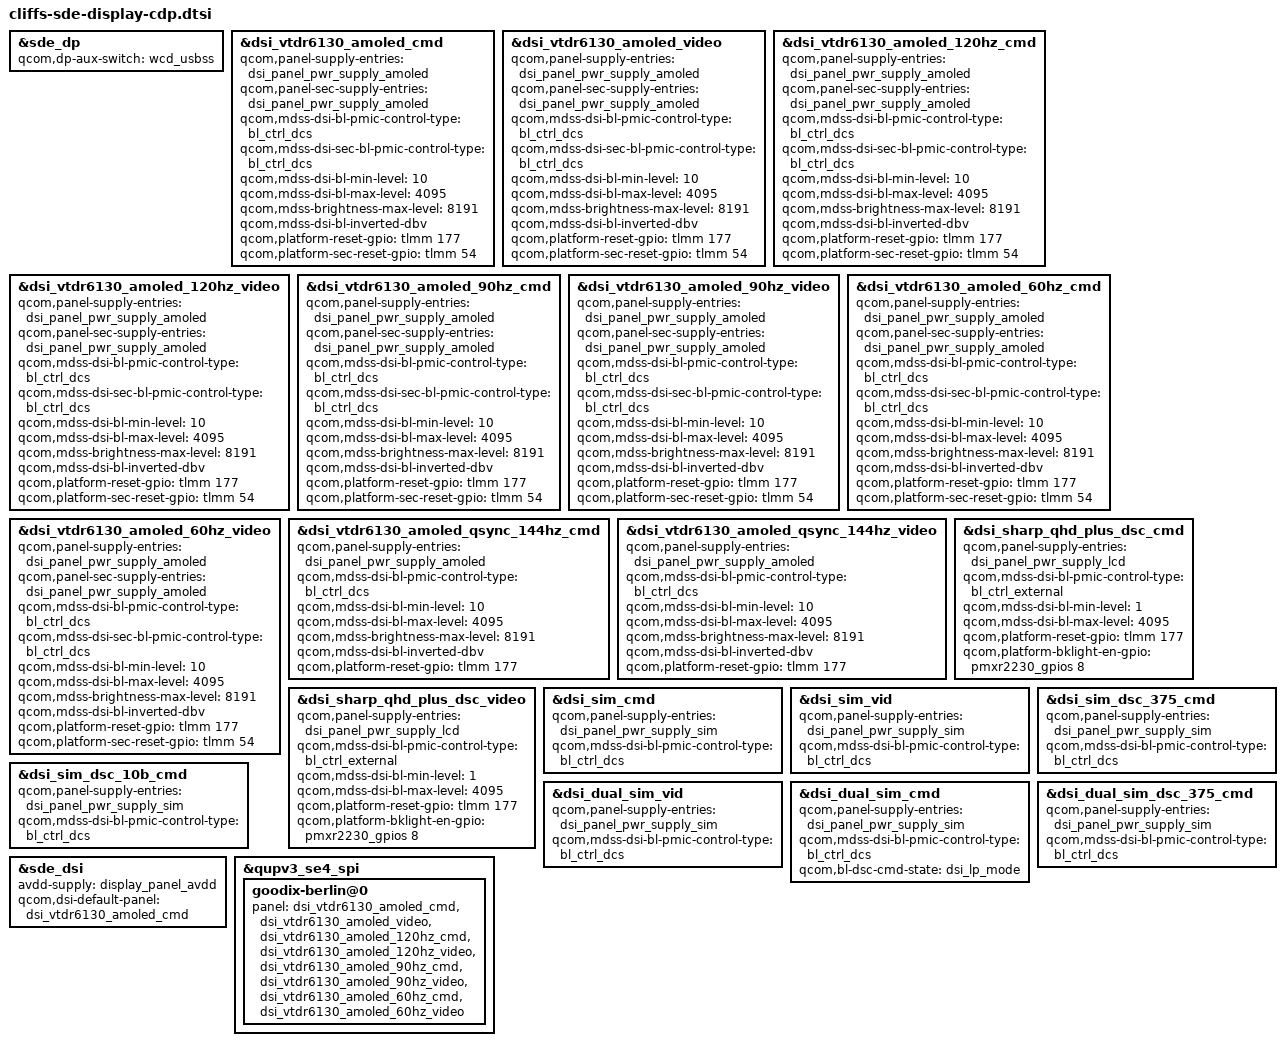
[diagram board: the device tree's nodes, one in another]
#include "cliffs-sde-display.dtsi"

&sde_dp {
	qcom,dp-aux-switch = <&wcd_usbss>;
};

&dsi_vtdr6130_amoled_cmd {
	qcom,panel-supply-entries = <&dsi_panel_pwr_supply_amoled>;
	qcom,panel-sec-supply-entries = <&dsi_panel_pwr_supply_amoled>;
	qcom,mdss-dsi-bl-pmic-control-type = "bl_ctrl_dcs";
	qcom,mdss-dsi-sec-bl-pmic-control-type = "bl_ctrl_dcs";
	qcom,mdss-dsi-bl-min-level = <10>;
	qcom,mdss-dsi-bl-max-level = <4095>;
	qcom,mdss-brightness-max-level = <8191>;
	qcom,mdss-dsi-bl-inverted-dbv;
	qcom,platform-reset-gpio = <&tlmm 177 0>;
	qcom,platform-sec-reset-gpio = <&tlmm 54 0>;
};

&dsi_vtdr6130_amoled_video {
	qcom,panel-supply-entries = <&dsi_panel_pwr_supply_amoled>;
	qcom,panel-sec-supply-entries = <&dsi_panel_pwr_supply_amoled>;
	qcom,mdss-dsi-bl-pmic-control-type = "bl_ctrl_dcs";
	qcom,mdss-dsi-sec-bl-pmic-control-type = "bl_ctrl_dcs";
	qcom,mdss-dsi-bl-min-level = <10>;
	qcom,mdss-dsi-bl-max-level = <4095>;
	qcom,mdss-brightness-max-level = <8191>;
	qcom,mdss-dsi-bl-inverted-dbv;
	qcom,platform-reset-gpio = <&tlmm 177 0>;
	qcom,platform-sec-reset-gpio = <&tlmm 54 0>;
};

&dsi_vtdr6130_amoled_120hz_cmd {
	qcom,panel-supply-entries = <&dsi_panel_pwr_supply_amoled>;
	qcom,panel-sec-supply-entries = <&dsi_panel_pwr_supply_amoled>;
	qcom,mdss-dsi-bl-pmic-control-type = "bl_ctrl_dcs";
	qcom,mdss-dsi-sec-bl-pmic-control-type = "bl_ctrl_dcs";
	qcom,mdss-dsi-bl-min-level = <10>;
	qcom,mdss-dsi-bl-max-level = <4095>;
	qcom,mdss-brightness-max-level = <8191>;
	qcom,mdss-dsi-bl-inverted-dbv;
	qcom,platform-reset-gpio = <&tlmm 177 0>;
	qcom,platform-sec-reset-gpio = <&tlmm 54 0>;
};

&dsi_vtdr6130_amoled_120hz_video {
	qcom,panel-supply-entries = <&dsi_panel_pwr_supply_amoled>;
	qcom,panel-sec-supply-entries = <&dsi_panel_pwr_supply_amoled>;
	qcom,mdss-dsi-bl-pmic-control-type = "bl_ctrl_dcs";
	qcom,mdss-dsi-sec-bl-pmic-control-type = "bl_ctrl_dcs";
	qcom,mdss-dsi-bl-min-level = <10>;
	qcom,mdss-dsi-bl-max-level = <4095>;
	qcom,mdss-brightness-max-level = <8191>;
	qcom,mdss-dsi-bl-inverted-dbv;
	qcom,platform-reset-gpio = <&tlmm 177 0>;
	qcom,platform-sec-reset-gpio = <&tlmm 54 0>;
};

&dsi_vtdr6130_amoled_90hz_cmd {
	qcom,panel-supply-entries = <&dsi_panel_pwr_supply_amoled>;
	qcom,panel-sec-supply-entries = <&dsi_panel_pwr_supply_amoled>;
	qcom,mdss-dsi-bl-pmic-control-type = "bl_ctrl_dcs";
	qcom,mdss-dsi-sec-bl-pmic-control-type = "bl_ctrl_dcs";
	qcom,mdss-dsi-bl-min-level = <10>;
	qcom,mdss-dsi-bl-max-level = <4095>;
	qcom,mdss-brightness-max-level = <8191>;
	qcom,mdss-dsi-bl-inverted-dbv;
	qcom,platform-reset-gpio = <&tlmm 177 0>;
	qcom,platform-sec-reset-gpio = <&tlmm 54 0>;
};

&dsi_vtdr6130_amoled_90hz_video {
	qcom,panel-supply-entries = <&dsi_panel_pwr_supply_amoled>;
	qcom,panel-sec-supply-entries = <&dsi_panel_pwr_supply_amoled>;
	qcom,mdss-dsi-bl-pmic-control-type = "bl_ctrl_dcs";
	qcom,mdss-dsi-sec-bl-pmic-control-type = "bl_ctrl_dcs";
	qcom,mdss-dsi-bl-min-level = <10>;
	qcom,mdss-dsi-bl-max-level = <4095>;
	qcom,mdss-brightness-max-level = <8191>;
	qcom,mdss-dsi-bl-inverted-dbv;
	qcom,platform-reset-gpio = <&tlmm 177 0>;
	qcom,platform-sec-reset-gpio = <&tlmm 54 0>;
};

&dsi_vtdr6130_amoled_60hz_cmd {
	qcom,panel-supply-entries = <&dsi_panel_pwr_supply_amoled>;
	qcom,panel-sec-supply-entries = <&dsi_panel_pwr_supply_amoled>;
	qcom,mdss-dsi-bl-pmic-control-type = "bl_ctrl_dcs";
	qcom,mdss-dsi-sec-bl-pmic-control-type = "bl_ctrl_dcs";
	qcom,mdss-dsi-bl-min-level = <10>;
	qcom,mdss-dsi-bl-max-level = <4095>;
	qcom,mdss-brightness-max-level = <8191>;
	qcom,mdss-dsi-bl-inverted-dbv;
	qcom,platform-reset-gpio = <&tlmm 177 0>;
	qcom,platform-sec-reset-gpio = <&tlmm 54 0>;
};

&dsi_vtdr6130_amoled_60hz_video {
	qcom,panel-supply-entries = <&dsi_panel_pwr_supply_amoled>;
	qcom,panel-sec-supply-entries = <&dsi_panel_pwr_supply_amoled>;
	qcom,mdss-dsi-bl-pmic-control-type = "bl_ctrl_dcs";
	qcom,mdss-dsi-sec-bl-pmic-control-type = "bl_ctrl_dcs";
	qcom,mdss-dsi-bl-min-level = <10>;
	qcom,mdss-dsi-bl-max-level = <4095>;
	qcom,mdss-brightness-max-level = <8191>;
	qcom,mdss-dsi-bl-inverted-dbv;
	qcom,platform-reset-gpio = <&tlmm 177 0>;
	qcom,platform-sec-reset-gpio = <&tlmm 54 0>;
};

&dsi_vtdr6130_amoled_qsync_144hz_cmd {
	qcom,panel-supply-entries = <&dsi_panel_pwr_supply_amoled>;
	qcom,mdss-dsi-bl-pmic-control-type = "bl_ctrl_dcs";
	qcom,mdss-dsi-bl-min-level = <10>;
	qcom,mdss-dsi-bl-max-level = <4095>;
	qcom,mdss-brightness-max-level = <8191>;
	qcom,mdss-dsi-bl-inverted-dbv;
	qcom,platform-reset-gpio = <&tlmm 177 0>;
};

&dsi_vtdr6130_amoled_qsync_144hz_video {
	qcom,panel-supply-entries = <&dsi_panel_pwr_supply_amoled>;
	qcom,mdss-dsi-bl-pmic-control-type = "bl_ctrl_dcs";
	qcom,mdss-dsi-bl-min-level = <10>;
	qcom,mdss-dsi-bl-max-level = <4095>;
	qcom,mdss-brightness-max-level = <8191>;
	qcom,mdss-dsi-bl-inverted-dbv;
	qcom,platform-reset-gpio = <&tlmm 177 0>;
};

&dsi_sharp_qhd_plus_dsc_cmd {
	qcom,panel-supply-entries = <&dsi_panel_pwr_supply_lcd>;
	qcom,mdss-dsi-bl-pmic-control-type = "bl_ctrl_external";
	qcom,mdss-dsi-bl-min-level = <1>;
	qcom,mdss-dsi-bl-max-level = <4095>;
	qcom,platform-reset-gpio = <&tlmm 177 0>;
	qcom,platform-bklight-en-gpio = <&pmxr2230_gpios 8 0>;
};

&dsi_sharp_qhd_plus_dsc_video {
	qcom,panel-supply-entries = <&dsi_panel_pwr_supply_lcd>;
	qcom,mdss-dsi-bl-pmic-control-type = "bl_ctrl_external";
	qcom,mdss-dsi-bl-min-level = <1>;
	qcom,mdss-dsi-bl-max-level = <4095>;
	qcom,platform-reset-gpio = <&tlmm 177 0>;
	qcom,platform-bklight-en-gpio = <&pmxr2230_gpios 8 0>;
};

&dsi_sim_cmd {
	qcom,panel-supply-entries = <&dsi_panel_pwr_supply_sim>;
	qcom,mdss-dsi-bl-pmic-control-type = "bl_ctrl_dcs";
};

&dsi_sim_vid {
	qcom,panel-supply-entries = <&dsi_panel_pwr_supply_sim>;
	qcom,mdss-dsi-bl-pmic-control-type = "bl_ctrl_dcs";
};

&dsi_sim_dsc_375_cmd {
	qcom,panel-supply-entries = <&dsi_panel_pwr_supply_sim>;
	qcom,mdss-dsi-bl-pmic-control-type = "bl_ctrl_dcs";
};

&dsi_sim_dsc_10b_cmd {
	qcom,panel-supply-entries = <&dsi_panel_pwr_supply_sim>;
	qcom,mdss-dsi-bl-pmic-control-type = "bl_ctrl_dcs";
};

&dsi_dual_sim_vid {
	qcom,panel-supply-entries = <&dsi_panel_pwr_supply_sim>;
	qcom,mdss-dsi-bl-pmic-control-type = "bl_ctrl_dcs";
};

&dsi_dual_sim_cmd {
	qcom,panel-supply-entries = <&dsi_panel_pwr_supply_sim>;
	qcom,mdss-dsi-bl-pmic-control-type = "bl_ctrl_dcs";
	qcom,bl-dsc-cmd-state = "dsi_lp_mode";
};

&dsi_dual_sim_dsc_375_cmd {
	qcom,panel-supply-entries = <&dsi_panel_pwr_supply_sim>;
	qcom,mdss-dsi-bl-pmic-control-type = "bl_ctrl_dcs";
};

&sde_dsi {
	avdd-supply = <&display_panel_avdd>;
	qcom,dsi-default-panel = <&dsi_vtdr6130_amoled_cmd>;
};

&qupv3_se4_spi {
	goodix-berlin@0 {
		panel = <&dsi_vtdr6130_amoled_cmd
			&dsi_vtdr6130_amoled_video
			&dsi_vtdr6130_amoled_120hz_cmd
			&dsi_vtdr6130_amoled_120hz_video
			&dsi_vtdr6130_amoled_90hz_cmd
			&dsi_vtdr6130_amoled_90hz_video
			&dsi_vtdr6130_amoled_60hz_cmd
			&dsi_vtdr6130_amoled_60hz_video>;
	};
};
